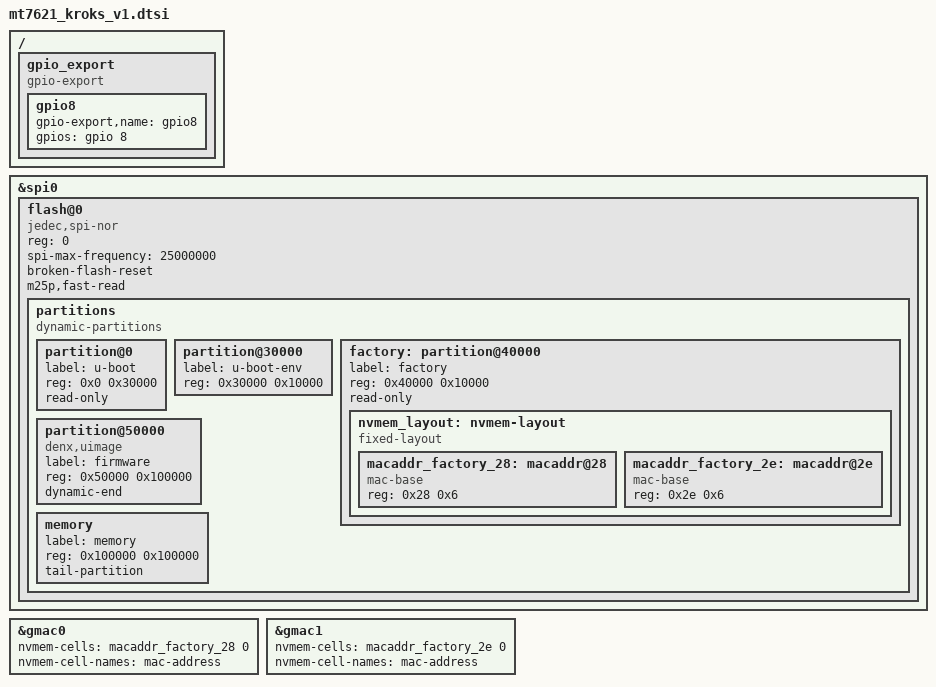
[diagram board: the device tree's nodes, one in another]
#include "mt7621_kroks.dtsi"

/ {
	gpio_export {
		compatible = "gpio-export";
		#size-cells = <0>;

		/* deprecated, only for compability with old versions */
		gpio8 {
			gpio-export,name = "gpio8";
			gpios = <&gpio 8 GPIO_ACTIVE_HIGH>;
		};
	};
};

&spi0 {
	status = "okay";

	/* Winbond W25Q256JV/W25Q256FV */
	flash@0 {
		compatible = "jedec,spi-nor";
		reg = <0>;
		spi-max-frequency = <25000000>;
		broken-flash-reset;
		m25p,fast-read;

		partitions {
			compatible = "dynamic-partitions";
			#address-cells = <1>;
			#size-cells = <1>;

			partition@0 {
				label = "u-boot";
				reg = <0x0 0x30000>;
				read-only;
			};

			partition@30000 {
				label = "u-boot-env";
				reg = <0x30000 0x10000>;
			};

			factory: partition@40000 {
				label = "factory";
				reg = <0x40000 0x10000>;
				read-only;
			};

			partition@50000 {
				compatible = "denx,uimage";
				label = "firmware";
				reg = <0x50000 0x100000>;
				dynamic-end;
			};

			memory {
				label = "memory";
				reg = <0x100000 0x100000>;
				tail-partition;
			};
		};
	};
};

&gmac0 {
	/* lan */
	nvmem-cells = <&macaddr_factory_28 0>;
	nvmem-cell-names = "mac-address";
};

&gmac1 {
	/* wan */
	nvmem-cells = <&macaddr_factory_2e 0>;
	nvmem-cell-names = "mac-address";
};

&factory {
	nvmem_layout: nvmem-layout {
		compatible = "fixed-layout";
		#address-cells = <1>;
		#size-cells = <1>;

		/* gmac0 */
		macaddr_factory_28: macaddr@28 {
			compatible = "mac-base";
			reg = <0x28 0x6>;
			#nvmem-cell-cells = <1>;
		};

		/* wan */
		macaddr_factory_2e: macaddr@2e {
			compatible = "mac-base";
			reg = <0x2e 0x6>;
			#nvmem-cell-cells = <1>;
		};
	};
};
